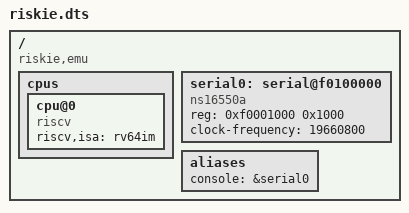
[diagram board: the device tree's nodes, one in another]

/dts-v1/;

/ {
	compatible = "riskie,emu";

	#address-cells = <1>;
	#size-cells = <1>;

	cpus {
		cpu@0 {
			compatible = "riscv";
			riscv,isa = "rv64im";
		};
	};

	serial0: serial@f0100000 {
		compatible = "ns16550a";
		reg = <0xf0001000 0x1000>;
		clock-frequency = <19660800>;
	};

	aliases {
		console = &serial0;
	};
};
